AUTOSAR XML (schema 4-0-3)
standard types defined: Boolean, UInt32, UInt8
package /AUTOSAR_Platform/DataConstrs
  range DC_Boolean: raw 0..1
  range DC_UInt8: raw 0..255
package /PATAC/MSM/ComponentTypes
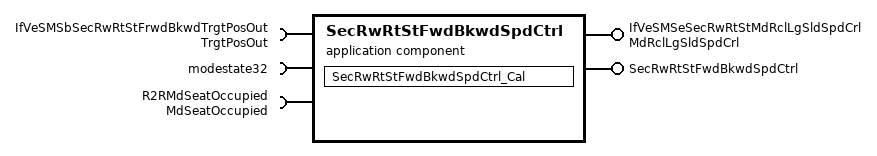
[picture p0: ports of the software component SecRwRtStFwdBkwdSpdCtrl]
  application sw component type SecRwRtStFwdBkwdSpdCtrl
    provide port IfVeSMSeSecRwRtStMdRclLgSldSpdCrl: nonqueued-sender-com-spec{data-element=MdRclLgSldSpdCrl/Val, init-value=0}, provided-interface=MdRclLgSldSpdCrl
    provide port SecRwRtStFwdBkwdSpdCtrl: server-com-spec{operation=Cal, queue-length=1}, provided-interface=SecRwRtStFwdBkwdSpdCtrl
    require port IfVeSMSbSecRwRtStFrwdBkwdTrgtPosOut: nonqueued-receiver-com-spec{data-element=TrgtPosOut/Val, filter=data-filter-type=ALWAYS, init-value=0}, required-interface=TrgtPosOut
    require port modestate32: nonqueued-receiver-com-spec{data-element=modestate32/Val, filter=data-filter-type=ALWAYS, init-value=0}, required-interface=modestate32
    require port R2RMdSeatOccupied: nonqueued-receiver-com-spec{data-element=MdSeatOccupied/Val, filter=data-filter-type=ALWAYS, init-value=0}, required-interface=MdSeatOccupied
    behavior SecRwRtStFwdBkwdSpdCtrl_InternalBehavior
      operation invoked event OIT_SecRwRtStFwdBkwdSpdCtrl_Cal_SecRwRtStFwdBkwdSpdCtrl_Cal: start-on-event=SecRwRtStFwdBkwdSpdCtrl_Cal, operation=SecRwRtStFwdBkwdSpdCtrl.Cal
      runnable SecRwRtStFwdBkwdSpdCtrl_Cal
        data-receive-point-by-arguments:
          access REC_IfVeSMSbSecRwRtStFrwdBkwdTrgtPosOut_Val: accessed-variable=IfVeSMSbSecRwRtStFrwdBkwdTrgtPosOut.Val
          access REC_modestate32_Val: accessed-variable=modestate32.Val
          access REC_R2RMdSeatOccupied_Val: accessed-variable=R2RMdSeatOccupied.Val
        data-send-points:
          access SEND_IfVeSMSeSecRwRtStMdRclLgSldSpdCrl_Val: accessed-variable=IfVeSMSeSecRwRtStMdRclLgSldSpdCrl.Val
  swc implementation SecRwRtStFwdBkwdSpdCtrl_Implementation: behavior=SecRwRtStFwdBkwdSpdCtrl_InternalBehavior
    code-descriptors:
      code Default: artifact-descriptors=autosar-engineering-object={short-label=Default, category=SWSRC}
package /PATAC/MSM/ModeAdjust/PortInterface
  client server interface SecRwRtStFwdBkwdSpdCtrl
    operation Cal
  4 x sender receiver interface:
    MdRclLgSldSpdCrl: invalidation-policy{data-element=MdRclLgSldSpdCrl/Val, handle-invalid=DONT-INVALIDATE}
      data Val: type=UInt8
    MdSeatOccupied: invalidation-policy{data-element=MdSeatOccupied/Val, handle-invalid=DONT-INVALIDATE}
      data Val: type=Boolean
    modestate32: invalidation-policy{data-element=modestate32/Val, handle-invalid=DONT-INVALIDATE}
      data Val: type=UInt32
    TrgtPosOut: invalidation-policy{data-element=TrgtPosOut/Val, handle-invalid=DONT-INVALIDATE}
      data Val: type=Boolean
